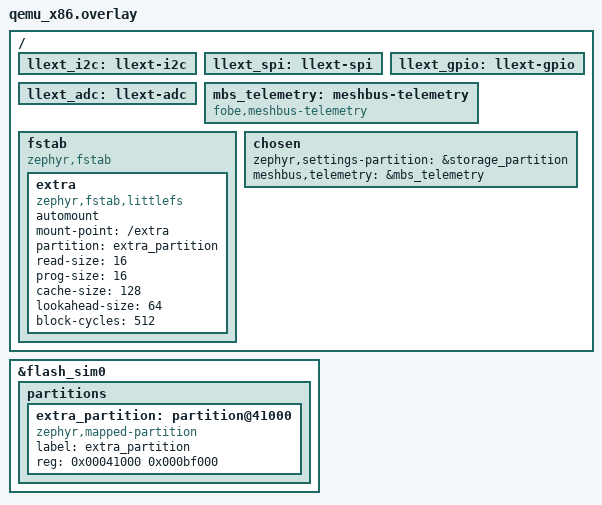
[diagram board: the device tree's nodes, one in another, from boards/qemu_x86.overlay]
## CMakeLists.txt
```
cmake_minimum_required(VERSION 3.20.0)

find_package(Zephyr REQUIRED HINTS $ENV{ZEPHYR_BASE})
project(mbs_llext_contract_test)

target_sources(app PRIVATE src/test_api.c src/peripheral_devices.c)

set(llext_targets)
set(llext_outputs)
set(ext_peripheral_bin ${PROJECT_BINARY_DIR}/llext/mbs_peripherals.mba)
set(ext_peripheral_inc ${ZEPHYR_BINARY_DIR}/include/generated/mbs_peripherals.inc)
add_llext_target(mbs_peripheral_ext
	OUTPUT ${ext_peripheral_bin}
	SOURCES ${CMAKE_CURRENT_SOURCE_DIR}/src/peripheral_ext.c
)
list(APPEND llext_targets mbs_peripheral_ext)
list(APPEND llext_outputs ${ext_peripheral_bin})
generate_inc_file_for_target(app ${ext_peripheral_bin} ${ext_peripheral_inc})


set(ext_app_bin ${PROJECT_BINARY_DIR}/llext/mbs_app.mba)
set(ext_app_inc ${ZEPHYR_BINARY_DIR}/include/generated/mbs_app.inc)
set(ext_other_edk_app_bin ${PROJECT_BINARY_DIR}/llext/mbs_otheredk.mba)
set(ext_other_edk_app_inc ${ZEPHYR_BINARY_DIR}/include/generated/mbs_otheredk_app.inc)
set(ext_older_edk_app_bin ${PROJECT_BINARY_DIR}/llext/mbs_olderedk.mba)
set(ext_older_edk_app_inc ${ZEPHYR_BINARY_DIR}/include/generated/mbs_olderedk_app.inc)
set(ext_bad_target_app_bin ${PROJECT_BINARY_DIR}/llext/mbs_badtargetapp.mba)
set(ext_bad_target_app_inc ${ZEPHYR_BINARY_DIR}/include/generated/mbs_badtarget_app.inc)
set(ext_unsupported_metadata_app_bin ${PROJECT_BINARY_DIR}/llext/mbs_unsupportedmeta.mba)
set(ext_unsupported_metadata_app_inc ${ZEPHYR_BINARY_DIR}/include/generated/mbs_unsupportedmeta_app.inc)
set(ext_bad_reserved_app_bin ${PROJECT_BINARY_DIR}/llext/mbs_badreserved.mba)
set(ext_bad_reserved_app_inc ${ZEPHYR_BINARY_DIR}/include/generated/mbs_badreserved_app.inc)
set(ext_big_app_bin ${PROJECT_BINARY_DIR}/llext/mbs_bigapp.mba)
set(ext_big_app_inc ${ZEPHYR_BINARY_DIR}/include/generated/mbs_bigapp.inc)
set(ext_bad_icon_app_bin ${PROJECT_BINARY_DIR}/llext/mbs_badicon.mba)
set(ext_bad_icon_app_inc ${ZEPHYR_BINARY_DIR}/include/generated/mbs_badicon.inc)
set(ext_bad_symbol_app_bin ${PROJECT_BINARY_DIR}/llext/mbs_badsymapp.mba)
set(ext_bad_symbol_app_inc ${ZEPHYR_BINARY_DIR}/include/generated/mbs_badsymapp.inc)

set(MBS_LLEXT_REUSE_APP "" CACHE FILEPATH
	"Existing compatible app package to embed instead of rebuilding mbs_app")
if(MBS_LLEXT_REUSE_APP)
	get_filename_component(ext_app_bin "${MBS_LLEXT_REUSE_APP}"
		ABSOLUTE BASE_DIR "${CMAKE_BINARY_DIR}")
	if(NOT EXISTS "${ext_app_bin}")
		message(FATAL_ERROR "Reused LLEXT app does not exist: ${ext_app_bin}")
	endif()
else()
	add_llext_target(mbs_app_ext
		OUTPUT ${ext_app_bin}
		SOURCES ${CMAKE_CURRENT_SOURCE_DIR}/src/app_ext.c
	)
	list(APPEND llext_targets mbs_app_ext)
	list(APPEND llext_outputs ${ext_app_bin})
endif()
add_llext_target(mbs_otheredk_app_ext
	OUTPUT ${ext_other_edk_app_bin}
	SOURCES ${CMAKE_CURRENT_SOURCE_DIR}/src/app_other_edk_ext.c
)
add_llext_target(mbs_olderedk_app_ext
	OUTPUT ${ext_older_edk_app_bin}
	SOURCES ${CMAKE_CURRENT_SOURCE_DIR}/src/app_older_edk_ext.c
)
add_llext_target(mbs_badtarget_app_ext
	OUTPUT ${ext_bad_target_app_bin}
	SOURCES ${CMAKE_CURRENT_SOURCE_DIR}/src/app_bad_target_ext.c
)
add_llext_target(mbs_unsupportedmeta_app_ext
	OUTPUT ${ext_unsupported_metadata_app_bin}
	SOURCES ${CMAKE_CURRENT_SOURCE_DIR}/src/app_unsupported_metadata_ext.c
)
add_llext_target(mbs_badreserved_app_ext
	OUTPUT ${ext_bad_reserved_app_bin}
	SOURCES ${CMAKE_CURRENT_SOURCE_DIR}/src/app_bad_reserved_ext.c
)
add_llext_target(mbs_bigapp_ext
	OUTPUT ${ext_big_app_bin}
	SOURCES ${CMAKE_CURRENT_SOURCE_DIR}/src/app_big_heap_ext.c
)
add_llext_target(mbs_badicon_ext
	OUTPUT ${ext_bad_icon_app_bin}
	SOURCES ${CMAKE_CURRENT_SOURCE_DIR}/src/app_bad_icon_ext.c
)
add_llext_target(mbs_badsymapp_ext
	OUTPUT ${ext_bad_symbol_app_bin}
	SOURCES ${CMAKE_CURRENT_SOURCE_DIR}/src/app_bad_symbol_ext.c
)

list(APPEND llext_targets
	mbs_otheredk_app_ext
	mbs_olderedk_app_ext
	mbs_badtarget_app_ext
	mbs_unsupportedmeta_app_ext
	mbs_badreserved_app_ext
	mbs_bigapp_ext
	mbs_badicon_ext
	mbs_badsymapp_ext
)
list(APPEND llext_outputs
	${ext_other_edk_app_bin}
	${ext_older_edk_app_bin}
	${ext_bad_target_app_bin}
	${ext_unsupported_metadata_app_bin}
	${ext_bad_reserved_app_bin}
	${ext_big_app_bin}
	${ext_bad_icon_app_bin}
	${ext_bad_symbol_app_bin}
)

generate_inc_file_for_target(app ${ext_app_bin} ${ext_app_inc})
generate_inc_file_for_target(app ${ext_other_edk_app_bin} ${ext_other_edk_app_inc})
generate_inc_file_for_target(app ${ext_older_edk_app_bin} ${ext_older_edk_app_inc})
generate_inc_file_for_target(app ${ext_bad_target_app_bin} ${ext_bad_target_app_inc})
generate_inc_file_for_target(app ${ext_unsupported_metadata_app_bin} ${ext_unsupported_metadata_app_inc})
generate_inc_file_for_target(app ${ext_bad_reserved_app_bin} ${ext_bad_reserved_app_inc})
generate_inc_file_for_target(app ${ext_big_app_bin} ${ext_big_app_inc})
generate_inc_file_for_target(app ${ext_bad_icon_app_bin} ${ext_bad_icon_app_inc})
generate_inc_file_for_target(app ${ext_bad_symbol_app_bin} ${ext_bad_symbol_app_inc})

foreach(llext_target ${llext_targets})
	if(TARGET ${llext_target}_llext_lib AND TARGET mbs_proto)
		add_dependencies(${llext_target}_llext_lib mbs_proto)
	endif()
	# Zephyr's processing target is order-only. Track the object files too,
	# so incremental builds do not embed an old MBA after its source changes.
	get_target_property(llext_lib_type ${llext_target}_llext_lib TYPE)
	if(llext_lib_type STREQUAL "OBJECT_LIBRARY")
		add_custom_command(
			OUTPUT ${PROJECT_BINARY_DIR}/llext/${llext_target}_debug.elf
			APPEND
			DEPENDS $<TARGET_OBJECTS:${llext_target}_llext_lib>
		)
	endif()
endforeach()

foreach(ext ${llext_outputs})
	add_custom_command(
		OUTPUT ${ext}
		APPEND
		COMMAND ${CMAKE_OBJCOPY}
			--set-section-flags
			.meshbus.llext.meta=contents,readonly
			${ext}
	)
endforeach()
```

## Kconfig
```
mainmenu "Meshbus LLEXT contract tests"

source "Kconfig.zephyr"

config MBS_LLEXT_TEST_ADD_SYSTEM_HEAP
	bool "Add the test-only LLEXT system heap requirement"
	default n

config HEAP_MEM_POOL_ADD_SIZE_MBS_LLEXT_TEST
	int
	default 196608 if MBS_LLEXT_TEST_ADD_SYSTEM_HEAP
	default 0
	help
	  Test-only subsystem heap requirement used to verify that LLEXT admission
	  follows Zephyr's final K_HEAP_MEM_POOL_SIZE rather than only the base
	  CONFIG_HEAP_MEM_POOL_SIZE.
```

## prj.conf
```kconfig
# SPDX-FileCopyrightText: FoBE Studio
# SPDX-License-Identifier: Apache-2.0

CONFIG_ZTEST=y
CONFIG_ASSERT=y
CONFIG_LOG=y

CONFIG_MBS=y
CONFIG_MBS_SHELL=y
CONFIG_MBS_LLEXT=y
CONFIG_MBS_LLEXT_SHELL=y
CONFIG_MBS_LLEXT_DEFAULT_ENABLED=y
CONFIG_MBS_LLEXT_DYNAMIC_HEAP_MARGIN_PERCENT=5
CONFIG_MBS_SETTINGS_PERSISTENCE_DELAY=50

CONFIG_LLEXT=y
# Native driver calls from a loaded MBA use test-owned DT devices.
CONFIG_I2C=y
CONFIG_SPI=y
CONFIG_GPIO=y
CONFIG_ADC=y
CONFIG_LLEXT_HEAP_DYNAMIC=y
CONFIG_LLEXT_SHELL=n
CONFIG_ZBUS_PRIORITY_BOOST=n
CONFIG_ZBUS_RUNTIME_OBSERVERS=y

CONFIG_FILE_SYSTEM=y
CONFIG_FILE_SYSTEM_LITTLEFS=y
CONFIG_FS_LITTLEFS_FMP_DEV=y
CONFIG_FLASH=y
CONFIG_FLASH_MAP=y
CONFIG_FLASH_SIMULATOR=y

CONFIG_SETTINGS=y
CONFIG_SETTINGS_ZMS=y
CONFIG_SETTINGS_ZMS_LL_CACHE=y
CONFIG_SETTINGS_ZMS_LL_CACHE_SIZE=512
CONFIG_ZMS=y
CONFIG_ZMS_LOOKUP_CACHE=y
CONFIG_ZMS_LOOKUP_CACHE_SIZE=512
CONFIG_ZMS_LOOKUP_CACHE_FOR_SETTINGS=y

CONFIG_SHELL=y
CONFIG_SHELL_BACKEND_DUMMY=y
CONFIG_SHELL_BACKEND_SERIAL=n

CONFIG_MAIN_STACK_SIZE=4096
CONFIG_SYSTEM_WORKQUEUE_STACK_SIZE=4096
CONFIG_ZTEST_STACK_SIZE=4096
CONFIG_HEAP_MEM_POOL_SIZE=196608
CONFIG_THREAD_STACK_INFO=y

# Application service bridges
CONFIG_SENSOR=y
CONFIG_MBS_TELEMETRY=y
CONFIG_MBS_TELEMETRY_DEFAULT_ENABLED=n
CONFIG_MBS_TELEMETRY_SHELL=n
CONFIG_MBS_TELEMETRY_STATS=n
CONFIG_MBS_NOTIFY=y
CONFIG_MBS_NOTIFY_SHELL=n
CONFIG_INPUT=y
CONFIG_MBS_INPUT=y
CONFIG_MBS_INPUT_SHELL=n
```

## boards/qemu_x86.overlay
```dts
&flash_sim0 {
	partitions {
		extra_partition: partition@41000 {
			compatible = "zephyr,mapped-partition";
			label = "extra_partition";
			reg = <0x00041000 0x000bf000>;
		};
	};
};

/ {
	/* Implemented by peripheral_devices.c, without physical controllers. */
	llext_i2c: llext-i2c {};
	llext_spi: llext-spi {};
	llext_gpio: llext-gpio {};
	llext_adc: llext-adc {};

	mbs_telemetry: meshbus-telemetry {
		compatible = "fobe,meshbus-telemetry";
	};

	fstab: fstab {
		compatible = "zephyr,fstab";
		extra: extra {
			compatible = "zephyr,fstab,littlefs";
			automount;
			mount-point = "/extra";
			partition = <&extra_partition>;
			read-size = <16>;
			prog-size = <16>;
			cache-size = <128>;
			lookahead-size = <64>;
			block-cycles = <512>;
		};
	};

	chosen {
		zephyr,settings-partition = &storage_partition;
		meshbus,telemetry = &mbs_telemetry;
	};
};
```

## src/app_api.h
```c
/* SPDX-FileCopyrightText: FoBE Studio */
/* SPDX-License-Identifier: Apache-2.0 */

#ifndef MBS_LLEXT_TEST_APP_API_H_
#define MBS_LLEXT_TEST_APP_API_H_

#include <stdint.h>

struct peripheral_result {
	int ready_mask;
	int i2c_rc;
	int spi_rc;
	int gpio_rc;
	int gpio_value;
	int adc_setup_rc;
	int adc_read_rc;
	int adc_mv_rc;
	int32_t adc_mv;
	uint8_t i2c_value;
	uint8_t spi_value;
	int16_t adc_value;
};

#define MBS_LLEXT_TEST_EVT_APP 3

int mbs_llext_test_hook(int event);

#endif /* MBS_LLEXT_TEST_APP_API_H_ */
```

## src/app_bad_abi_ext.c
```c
/* SPDX-License-Identifier: Apache-2.0 */
#include <llext/metadata.h>
#include <zephyr/llext/symbol.h>
#include "app_api.h"

static const struct mbs_llext_app_metadata metadata MBS_LLEXT_APP_METADATA_ATTR = {
	.magic = MBS_LLEXT_APP_METADATA_MAGIC,
	.metadata_version = 2U,
	.size = sizeof(struct mbs_llext_app_metadata),
	.stack_size = 1024U,
	.heap_size = 16384U,
	.id = "mbs_badabi",
	.name = "Bad ABI constructor",
	.app_version = "1.0.0",
	.entry_point_symbol = "app_bad_abi_entry",
	.edk_version = "1.0.0",
	.compatibility_reserved = {0xff, 0xff, 0xff, 0x7f},
	.target = CONFIG_BOARD_TARGET,
};

static void __attribute__((constructor)) forbidden_constructor(void)
{
	mbs_llext_test_hook(MBS_LLEXT_TEST_EVT_APP);
}

void app_bad_abi_entry(void *args)
{
	(void)args;
	mbs_llext_test_hook(MBS_LLEXT_TEST_EVT_APP);
}
EXPORT_SYMBOL(app_bad_abi_entry);
```

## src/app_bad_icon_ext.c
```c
/* SPDX-FileCopyrightText: FoBE Studio */
/* SPDX-License-Identifier: Apache-2.0 */

#include <zephyr/kernel.h>
#include <zephyr/llext/symbol.h>
#include <llext/metadata.h>

static const struct mbs_llext_app_metadata app_metadata
	MBS_LLEXT_APP_METADATA_ATTR = {
		.magic = MBS_LLEXT_APP_METADATA_MAGIC,
		.metadata_version = MBS_LLEXT_APP_METADATA_VERSION,
		.size = sizeof(struct mbs_llext_app_metadata),
		.stack_size = 1024U,
		.heap_size = 16384U,
		.icon_data_size = 1U,
		.id = "mbs_badicon",
		.name = "Bad Icon App",
		.app_version = "1.0.0",
		.entry_point_symbol = "app_bad_icon_entry",
		.edk_version = "0.1.0",
		.target = CONFIG_BOARD_TARGET,
		.icon_data = {0xff},
	};

void app_bad_icon_entry(void *args)
{
	ARG_UNUSED(args);
}
EXPORT_SYMBOL(app_bad_icon_entry);
```

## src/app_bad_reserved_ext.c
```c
/* SPDX-FileCopyrightText: FoBE Studio */
/* SPDX-License-Identifier: Apache-2.0 */

#include <zephyr/kernel.h>
#include <zephyr/llext/symbol.h>
#include <llext/metadata.h>

static const struct mbs_llext_app_metadata app_metadata
	MBS_LLEXT_APP_METADATA_ATTR = {
		.magic = MBS_LLEXT_APP_METADATA_MAGIC,
		.metadata_version = MBS_LLEXT_APP_METADATA_VERSION,
		.size = sizeof(struct mbs_llext_app_metadata),
		.stack_size = 1024U,
		.heap_size = 16384U,
		.id = "mbs_badreserved",
		.name = "Bad Reserved App",
		.app_version = "1.0.0",
		.entry_point_symbol = "app_bad_reserved_entry",
		.edk_version = "0.1.0",
		.reserved_header = {1U},
		.target = CONFIG_BOARD_TARGET,
	};

void app_bad_reserved_entry(void *args)
{
	ARG_UNUSED(args);
}
EXPORT_SYMBOL(app_bad_reserved_entry);
```

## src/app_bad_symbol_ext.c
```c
/* SPDX-FileCopyrightText: FoBE Studio */
/* SPDX-License-Identifier: Apache-2.0 */

#include <llext/metadata.h>
#include <zephyr/llext/symbol.h>

static const struct mbs_llext_app_metadata app_metadata
	MBS_LLEXT_APP_METADATA_ATTR = {
		.magic = MBS_LLEXT_APP_METADATA_MAGIC,
		.metadata_version = MBS_LLEXT_APP_METADATA_VERSION,
		.size = sizeof(struct mbs_llext_app_metadata),
		.stack_size = 1024U,
		.heap_size = 32768U,
		.icon_data_size = 0U,
		.id = "mbs_badsymapp",
		.name = "Missing Symbol App",
		.app_version = "1.0.0",
		.entry_point_symbol = "missing_app_entry",
		.edk_version = "0.1.0",
		.target = CONFIG_BOARD_TARGET,
	};

void present_app_symbol(void)
{
}
EXPORT_SYMBOL(present_app_symbol);
```

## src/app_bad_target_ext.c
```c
/* SPDX-FileCopyrightText: FoBE Studio */
/* SPDX-License-Identifier: Apache-2.0 */

#include <zephyr/kernel.h>
#include <zephyr/llext/symbol.h>
#include <llext/metadata.h>

static const struct mbs_llext_app_metadata app_metadata
	MBS_LLEXT_APP_METADATA_ATTR = {
		.magic = MBS_LLEXT_APP_METADATA_MAGIC,
		.metadata_version = MBS_LLEXT_APP_METADATA_VERSION,
		.size = sizeof(struct mbs_llext_app_metadata),
		.stack_size = 1024U,
		.heap_size = 16384U,
		.id = "mbs_badtargetapp",
		.name = "Bad Target App",
		.app_version = "1.0.0",
		.entry_point_symbol = "app_bad_target_entry",
		.edk_version = "0.1.0",
		.target = "other/target",
	};

void app_bad_target_entry(void *args)
{
	ARG_UNUSED(args);
}
EXPORT_SYMBOL(app_bad_target_entry);
```

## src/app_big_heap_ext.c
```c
/* SPDX-FileCopyrightText: FoBE Studio */
/* SPDX-License-Identifier: Apache-2.0 */

#include <zephyr/kernel.h>
#include <zephyr/llext/symbol.h>
#include <llext/metadata.h>

static const struct mbs_llext_app_metadata app_metadata
	MBS_LLEXT_APP_METADATA_ATTR = {
		.magic = MBS_LLEXT_APP_METADATA_MAGIC,
		.metadata_version = MBS_LLEXT_APP_METADATA_VERSION,
		.size = sizeof(struct mbs_llext_app_metadata),
		.stack_size = 1024U,
		.heap_size = CONFIG_MBS_LLEXT_APP_HEAP_RESERVE_SIZE + 1U,
		.icon_data_size = 0U,
		.id = "mbs_bigapp",
		.name = "Big App",
		.app_version = "1.0.0",
		.entry_point_symbol = "app_big_heap_entry",
		.edk_version = "0.1.0",
		.target = CONFIG_BOARD_TARGET,
	};

void app_big_heap_entry(void *args)
{
	ARG_UNUSED(args);
}
EXPORT_SYMBOL(app_big_heap_entry);
```

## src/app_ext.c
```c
/* SPDX-License-Identifier: Apache-2.0 */
/*
 * Copyright (c) 2026 FoBE Studio
 */

#include <zephyr/kernel.h>
#include <zephyr/llext/symbol.h>
#include <llext/metadata.h>

#include "app_api.h"

static const struct mbs_llext_app_metadata app_metadata
	MBS_LLEXT_APP_METADATA_ATTR = {
		.magic = MBS_LLEXT_APP_METADATA_MAGIC,
		.metadata_version = MBS_LLEXT_APP_METADATA_VERSION,
		.size = sizeof(struct mbs_llext_app_metadata),
		.stack_size = 1024U,
		.heap_size = 32768U,
		.icon_data_size = MBS_LLEXT_APP_ICON_DATA_SIZE,
		.id = "mbs_app",
		.name = "Meshbus App",
		.app_version = "1.0.0",
		.entry_point_symbol = "app_test_entry",
		.edk_version = "0.1.0",
		.target = CONFIG_BOARD_TARGET,
		.icon_data = {
			0x00, 0x03, 0x7c, 0x02, 0x44, 0x02, 0x44, 0x02, 0x7c, 0x02,
			0x44, 0x02, 0x44, 0x02, 0x44, 0x02, 0x7c, 0x02, 0x00, 0x00,
		},
	};

void app_test_entry(void *args)
{
	ARG_UNUSED(args);

	(void)mbs_llext_test_hook(MBS_LLEXT_TEST_EVT_APP);
}
EXPORT_SYMBOL(app_test_entry);
```

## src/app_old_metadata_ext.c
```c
// SPDX-License-Identifier: Apache-2.0

#include <zephyr/kernel.h>
#include <zephyr/llext/symbol.h>
#include <llext/metadata.h>

static const struct mbs_llext_app_metadata app_metadata
	MBS_LLEXT_APP_METADATA_ATTR = {
		.magic = MBS_LLEXT_APP_METADATA_MAGIC,
		.metadata_version = MBS_LLEXT_APP_METADATA_VERSION + 1U,
		.size = sizeof(struct mbs_llext_app_metadata),
		.stack_size = 1024U,
		.heap_size = 16384U,
		.id = "mbs_oldmeta",
		.name = "Old Metadata App",
		.app_version = "1.0.0",
		.entry_point_symbol = "app_old_metadata_entry",
		.edk_version = "0.1.0",
		.target = CONFIG_BOARD_TARGET,
	};

void app_old_metadata_entry(void *args)
{
	ARG_UNUSED(args);
}
EXPORT_SYMBOL(app_old_metadata_entry);
```

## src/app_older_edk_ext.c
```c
/* SPDX-FileCopyrightText: FoBE Studio */
/* SPDX-License-Identifier: Apache-2.0 */

#include <zephyr/kernel.h>
#include <zephyr/llext/symbol.h>
#include <llext/metadata.h>

static const struct mbs_llext_app_metadata app_metadata
	MBS_LLEXT_APP_METADATA_ATTR = {
		.magic = MBS_LLEXT_APP_METADATA_MAGIC,
		.metadata_version = MBS_LLEXT_APP_METADATA_VERSION,
		.size = sizeof(struct mbs_llext_app_metadata),
		.stack_size = 1024U,
		.heap_size = 32768U,
		.id = "mbs_olderedk",
		.name = "Older EDK",
		.app_version = "1.0.0",
		.entry_point_symbol = "app_older_edk_entry",
		.edk_version = "0.0.1",
		.target = CONFIG_BOARD_TARGET,
	};

void app_older_edk_entry(void *args)
{
	ARG_UNUSED(args);
}
EXPORT_SYMBOL(app_older_edk_entry);
```

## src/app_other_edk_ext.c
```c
/* SPDX-FileCopyrightText: FoBE Studio */
/* SPDX-License-Identifier: Apache-2.0 */

#include <zephyr/kernel.h>
#include <zephyr/llext/symbol.h>
#include <llext/metadata.h>

static const struct mbs_llext_app_metadata app_metadata
	MBS_LLEXT_APP_METADATA_ATTR = {
		.magic = MBS_LLEXT_APP_METADATA_MAGIC,
		.metadata_version = MBS_LLEXT_APP_METADATA_VERSION,
		.size = sizeof(struct mbs_llext_app_metadata),
		.stack_size = 1024U,
		.heap_size = 32768U,
		.id = "mbs_otheredk",
		.name = "Different EDK",
		.app_version = "1.0.0",
		.entry_point_symbol = "app_other_edk_entry",
		.edk_version = "9.0.0",
		.target = CONFIG_BOARD_TARGET,
	};

void app_other_edk_entry(void *args)
{
	ARG_UNUSED(args);
}
EXPORT_SYMBOL(app_other_edk_entry);
```

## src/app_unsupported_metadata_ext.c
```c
/* SPDX-FileCopyrightText: FoBE Studio */
/* SPDX-License-Identifier: Apache-2.0 */

#include <zephyr/kernel.h>
#include <zephyr/llext/symbol.h>
#include <llext/metadata.h>

#include "app_api.h"

static const struct mbs_llext_app_metadata app_metadata
	MBS_LLEXT_APP_METADATA_ATTR = {
		.magic = MBS_LLEXT_APP_METADATA_MAGIC,
		.metadata_version = MBS_LLEXT_APP_METADATA_VERSION + 1U,
		.size = sizeof(struct mbs_llext_app_metadata),
		.stack_size = 1024U,
		.heap_size = 16384U,
		.id = "mbs_unsupportedmeta",
		.name = "Unsupported Metadata App",
		.app_version = "1.0.0",
		.entry_point_symbol = "app_unsupported_metadata_entry",
		.edk_version = "0.1.0",
		.target = CONFIG_BOARD_TARGET,
	};

static void __attribute__((constructor)) forbidden_constructor(void)
{
	mbs_llext_test_hook(MBS_LLEXT_TEST_EVT_APP);
}

void app_unsupported_metadata_entry(void *args)
{
	ARG_UNUSED(args);
	mbs_llext_test_hook(MBS_LLEXT_TEST_EVT_APP);
}
EXPORT_SYMBOL(app_unsupported_metadata_entry);
```
